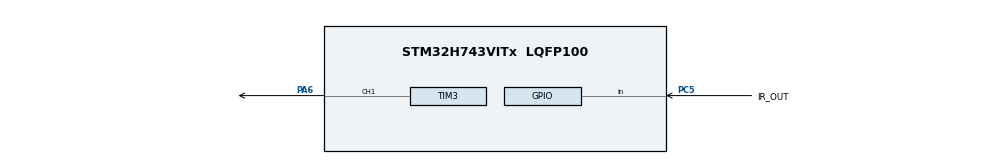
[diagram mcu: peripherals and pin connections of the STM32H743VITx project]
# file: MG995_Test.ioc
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CORTEX_M7.default_mode_Activation=1
Mcu.Family=STM32H7
Mcu.Name=STM32H743VITx
Mcu.Package=LQFP100
NVIC.PriorityGroup=NVIC_PRIORITYGROUP_4
PA6.Signal=S_TIM3_CH1
PC5.GPIO_Label=IR_OUT
PC5.GPIO_PuPd=GPIO_PULLUP
PC5.Signal=GPIO_Input
ProjectManager.HeapSize=0x200
ProjectManager.StackSize=0x400
ProjectManager.TargetToolchain=STM32CubeIDE
RCC.ADCFreq_Value=129000000
RCC.APB1Freq_Value=64000000
RCC.APB2Freq_Value=64000000
RCC.APB3Freq_Value=64000000
RCC.APB4Freq_Value=64000000
RCC.CortexFreq_Value=64000000
RCC.HCLKFreq_Value=64000000
RCC.SYSCLKFreq_VALUE=64000000
RCC.USBFreq_Value=129000000
SH.S_TIM3_CH1.0=TIM3_CH1,PWM Generation1 CH1
TIM3.Channel-PWM\ Generation1\ CH1=TIM_CHANNEL_1
TIM3.Period=19999
TIM3.Prescaler=63
TIM3.Pulse-PWM\ Generation1\ CH1=1500
VP_MEMORYMAP_VS_MEMORYMAP.Mode=CurAppReg
VP_TIM3_VS_ClockSourceINT.Mode=Internal
board=custom

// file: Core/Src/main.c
/* USER CODE BEGIN Header */
/**
  ******************************************************************************
  * @file           : main.c
  * @brief          : Main program body
  ******************************************************************************
  * @attention
  *
  * Copyright (c) 2026 STMicroelectronics.
  * All rights reserved.
  *
  * This software is licensed under terms that can be found in the LICENSE file
  * in the root directory of this software component.
  * If no LICENSE file comes with this software, it is provided AS-IS.
  *
  ******************************************************************************
  */
/* USER CODE END Header */

#include "main.h"
#include "tim.h"
#include "gpio.h"

/* USER CODE BEGIN PD */

/*
  연속회전형처럼 동작하는 서보 기준 PWM, 단위: us

  SERVO_STOP_US:
    - 모터 정지 신호
    - 보통 1500us 근처
    - 정지 상태에서도 살짝 움직이면 1480~1520 사이에서 조정

  SERVO_PUSH_US:
    - 세정제를 누르는 방향

  SERVO_RETURN_US:
    - 누른 뒤 다시 위로 올라가는 방향
*/
#define SERVO_STOP_US           1500
#define SERVO_PUSH_US           2000
#define SERVO_RETURN_US         1000

/*
  동작 시간 설정

  PUSH_TIME_MS:
    - 누르는 시간
    - 너무 깊게 누르면 줄이기
    - 덜 눌리면 늘리기

  RETURN_TIME_MS:
    - 누른 뒤 위로 복귀하는 시간
    - 초기/복귀 위치가 너무 높으면 줄이기
    - 다시 위로 덜 올라가면 늘리기
*/
#define PUSH_TIME_MS            350
#define RETURN_TIME_MS          250

/*
  손 감지 후 반복 분사 방지용 대기 시간
*/
#define AFTER_ACTION_DELAY_MS   300

/*
  IR 센서 입력 핀
  CubeMX에서 PC5 = GPIO Input + Pull-up으로 설정되어 있어야 함
*/
#define IR_GPIO_PORT            GPIOC
#define IR_GPIO_PIN             GPIO_PIN_5

/* USER CODE END PD */

void SystemClock_Config(void);
static void MPU_Config(void);

/* USER CODE BEGIN PFP */
static void Servo_SetPulse(uint16_t pulse_us);
static void Servo_Stop(void);
static void Dispenser_PushAndReturn(void);
/* USER CODE END PFP */

/* USER CODE BEGIN 0 */

static void Servo_SetPulse(uint16_t pulse_us)
{
  __HAL_TIM_SET_COMPARE(&htim3, TIM_CHANNEL_1, pulse_us);
}

static void Servo_Stop(void)
{
  Servo_SetPulse(SERVO_STOP_US);
}

static void Dispenser_PushAndReturn(void)
{
  /*
    1. 손세정제 누르는 방향으로 회전
  */
  Servo_SetPulse(SERVO_PUSH_US);
  HAL_Delay(PUSH_TIME_MS);

  /*
    2. 누른 뒤 위쪽으로 복귀
  */
  Servo_SetPulse(SERVO_RETURN_US);
  HAL_Delay(RETURN_TIME_MS);

  /*
    3. 정지
  */
  Servo_Stop();
}

/* USER CODE END 0 */

int main(void)
{

  /* MPU Configuration--------------------------------------------------------*/
  MPU_Config();

  /* MCU Configuration--------------------------------------------------------*/

  /* Reset of all peripherals, Initializes the Flash interface and the Systick. */
  HAL_Init();

  /* Configure the system clock */
  SystemClock_Config();

  /* Initialize all configured peripherals */
  MX_GPIO_Init();
  MX_TIM3_Init();

  /* USER CODE BEGIN 2 */

  /*
    TIM3 CH1 PWM 시작
    PA6 = TIM3_CH1 = 서보 신호선
  */
  HAL_TIM_PWM_Start(&htim3, TIM_CHANNEL_1);

  /*
    초기 상태:
    위로 올리는 초기 보정 동작을 하지 않고 정지만 한다.
    기존 코드의 Dispenser_InitPosition() 때문에 초기 위치가 너무 높아질 수 있었음.
  */
  Servo_Stop();
  HAL_Delay(1000);

  /* USER CODE END 2 */

  /* Infinite loop */
  /* USER CODE BEGIN WHILE */
  while (1)
  {
    /*
      IR 센서가 Active-Low인 경우:
      손 감지됨 = GPIO_PIN_RESET
      손 없음   = GPIO_PIN_SET
    */
    if (HAL_GPIO_ReadPin(IR_GPIO_PORT, IR_GPIO_PIN) == GPIO_PIN_RESET)
    {
      /*
        손 감지 시:
        1회 누르기 + 복귀 동작
      */
      Dispenser_PushAndReturn();

      /*
        손을 계속 대고 있으면 반복 분사하지 않도록
        손이 빠질 때까지 정지 상태로 대기
      */
      while (HAL_GPIO_ReadPin(IR_GPIO_PORT, IR_GPIO_PIN) == GPIO_PIN_RESET)
      {
        Servo_Stop();
        HAL_Delay(20);
      }

      /*
        손이 빠진 직후 약간 대기
      */
      Servo_Stop();
      HAL_Delay(AFTER_ACTION_DELAY_MS);
    }
    else
    {
      /*
        손이 없으면 계속 정지 상태 유지
      */
      Servo_Stop();
    }

    HAL_Delay(20);

    /* USER CODE END WHILE */

  }
}

void SystemClock_Config(void)
{
  RCC_OscInitTypeDef RCC_OscInitStruct = {0};
  RCC_ClkInitTypeDef RCC_ClkInitStruct = {0};

  /** Supply configuration update enable
  */
  HAL_PWREx_ConfigSupply(PWR_LDO_SUPPLY);

  /** Configure the main internal regulator output voltage
  */
  __HAL_PWR_VOLTAGESCALING_CONFIG(PWR_REGULATOR_VOLTAGE_SCALE3);

  while(!__HAL_PWR_GET_FLAG(PWR_FLAG_VOSRDY)) {}

  /** Initializes the RCC Oscillators according to the specified parameters
  * in the RCC_OscInitTypeDef structure.
  */
  RCC_OscInitStruct.OscillatorType = RCC_OSCILLATORTYPE_HSI;
  RCC_OscInitStruct.HSIState = RCC_HSI_DIV1;
  RCC_OscInitStruct.HSICalibrationValue = RCC_HSICALIBRATION_DEFAULT;
  RCC_OscInitStruct.PLL.PLLState = RCC_PLL_NONE;

  if (HAL_RCC_OscConfig(&RCC_OscInitStruct) != HAL_OK)
  {
    Error_Handler();
  }

  /** Initializes the CPU, AHB and APB buses clocks
  */
  RCC_ClkInitStruct.ClockType = RCC_CLOCKTYPE_HCLK | RCC_CLOCKTYPE_SYSCLK
                              | RCC_CLOCKTYPE_PCLK1 | RCC_CLOCKTYPE_PCLK2
                              | RCC_CLOCKTYPE_D3PCLK1 | RCC_CLOCKTYPE_D1PCLK1;

  RCC_ClkInitStruct.SYSCLKSource = RCC_SYSCLKSOURCE_HSI;
  RCC_ClkInitStruct.SYSCLKDivider = RCC_SYSCLK_DIV1;
  RCC_ClkInitStruct.AHBCLKDivider = RCC_HCLK_DIV1;
  RCC_ClkInitStruct.APB3CLKDivider = RCC_APB3_DIV1;
  RCC_ClkInitStruct.APB1CLKDivider = RCC_APB1_DIV1;
  RCC_ClkInitStruct.APB2CLKDivider = RCC_APB2_DIV1;
  RCC_ClkInitStruct.APB4CLKDivider = RCC_APB4_DIV1;

  if (HAL_RCC_ClockConfig(&RCC_ClkInitStruct, FLASH_LATENCY_1) != HAL_OK)
  {
    Error_Handler();
  }
}

/* MPU Configuration */
void MPU_Config(void)
{
  MPU_Region_InitTypeDef MPU_InitStruct = {0};

  /* Disables the MPU */
  HAL_MPU_Disable();

  /** Initializes and configures the Region and the memory to be protected
  */
  MPU_InitStruct.Enable = MPU_REGION_ENABLE;
  MPU_InitStruct.Number = MPU_REGION_NUMBER0;
  MPU_InitStruct.BaseAddress = 0x0;
  MPU_InitStruct.Size = MPU_REGION_SIZE_4GB;
  MPU_InitStruct.SubRegionDisable = 0x87;
  MPU_InitStruct.TypeExtField = MPU_TEX_LEVEL0;
  MPU_InitStruct.AccessPermission = MPU_REGION_NO_ACCESS;
  MPU_InitStruct.DisableExec = MPU_INSTRUCTION_ACCESS_DISABLE;
  MPU_InitStruct.IsShareable = MPU_ACCESS_SHAREABLE;
  MPU_InitStruct.IsCacheable = MPU_ACCESS_NOT_CACHEABLE;
  MPU_InitStruct.IsBufferable = MPU_ACCESS_NOT_BUFFERABLE;

  HAL_MPU_ConfigRegion(&MPU_InitStruct);

  /* Enables the MPU */
  HAL_MPU_Enable(MPU_PRIVILEGED_DEFAULT);
}

void Error_Handler(void)
{
  __disable_irq();
  while (1)
  {
  }
}
